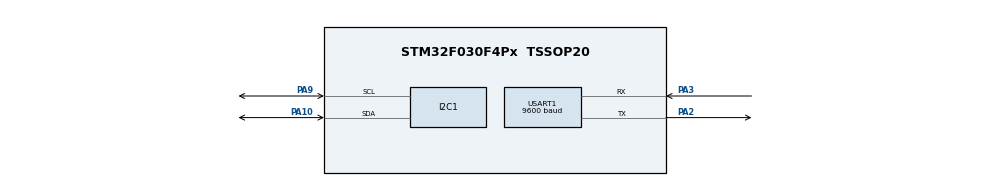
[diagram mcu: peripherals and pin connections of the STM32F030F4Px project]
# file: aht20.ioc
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I2C1.Timing=0x00201D2B
Mcu.Family=STM32F0
Mcu.Name=STM32F030F4Px
Mcu.Package=TSSOP20
PA10.Mode=I2C
PA10.Signal=I2C1_SDA
PA13.Mode=Serial_Wire
PA13.Signal=SYS_SWDIO
PA14.Mode=Serial_Wire
PA14.Signal=SYS_SWCLK
PA2.Mode=Asynchronous
PA2.Signal=USART1_TX
PA3.Mode=Asynchronous
PA3.Signal=USART1_RX
PA9.Mode=I2C
PA9.Signal=I2C1_SCL
ProjectManager.HeapSize=0x200
ProjectManager.StackSize=0x400
ProjectManager.TargetToolchain=EWARM V8.32
USART1.BaudRate=9600
USART1.VirtualMode-Asynchronous=VM_ASYNC
board=custom

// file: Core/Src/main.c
/* USER CODE BEGIN Header */
/**
  ******************************************************************************
  * @file           : main.c
  * @brief          : Main program body
  ******************************************************************************
  * @attention
  *
  * Copyright (c) 2025 STMicroelectronics.
  * All rights reserved.
  *
  * This software is licensed under terms that can be found in the LICENSE file
  * in the root directory of this software component.
  * If no LICENSE file comes with this software, it is provided AS-IS.
  *
  ******************************************************************************
  */
/* USER CODE END Header */
#include "main.h"

/* USER CODE BEGIN Includes */
#include "AHT20.h"
#include "stdio.h"

/* USER CODE END Includes */

I2C_HandleTypeDef hi2c1;

UART_HandleTypeDef huart1;

/* USER CODE BEGIN PV */
float temp = 0,humiditi = 0;
char ch[40];
/* USER CODE END PV */

void SystemClock_Config(void);
static void MX_GPIO_Init(void);
static void MX_I2C1_Init(void);
static void MX_USART1_UART_Init(void);

int main(void)
{

  /* MCU Configuration--------------------------------------------------------*/

  /* Reset of all peripherals, Initializes the Flash interface and the Systick. */
  HAL_Init();

  /* Configure the system clock */
  SystemClock_Config();

  /* Initialize all configured peripherals */
  MX_GPIO_Init();
  MX_I2C1_Init();
  MX_USART1_UART_Init();
  /* USER CODE BEGIN 2 */
 AHT20_init();
  HAL_StatusTypeDef res = AHT20_read(&temp,&humiditi);

  sprintf(ch,"%f",temp);
  HAL_UART_Transmit(&huart1,"temp = ",7,100);
    HAL_UART_Transmit(&huart1,ch,strlen(ch),100);
      HAL_UART_Transmit(&huart1," \r\n",3,100);

        sprintf(ch,"%f",humiditi);
  HAL_UART_Transmit(&huart1,"hum = ",6,100);
    HAL_UART_Transmit(&huart1,ch,strlen(ch),100);
      HAL_UART_Transmit(&huart1," \r\n",3,100);
  /* USER CODE END 2 */

  /* Infinite loop */
  while (1)
  {

  }
}

void SystemClock_Config(void)
{
  RCC_OscInitTypeDef RCC_OscInitStruct = {0};
  RCC_ClkInitTypeDef RCC_ClkInitStruct = {0};
  RCC_PeriphCLKInitTypeDef PeriphClkInit = {0};

  /** Initializes the RCC Oscillators according to the specified parameters
  * in the RCC_OscInitTypeDef structure.
  */
  RCC_OscInitStruct.OscillatorType = RCC_OSCILLATORTYPE_HSI;
  RCC_OscInitStruct.HSIState = RCC_HSI_ON;
  RCC_OscInitStruct.HSICalibrationValue = RCC_HSICALIBRATION_DEFAULT;
  RCC_OscInitStruct.PLL.PLLState = RCC_PLL_NONE;
  if (HAL_RCC_OscConfig(&RCC_OscInitStruct) != HAL_OK)
  {
    Error_Handler();
  }

  /** Initializes the CPU, AHB and APB buses clocks
  */
  RCC_ClkInitStruct.ClockType = RCC_CLOCKTYPE_HCLK|RCC_CLOCKTYPE_SYSCLK
                              |RCC_CLOCKTYPE_PCLK1;
  RCC_ClkInitStruct.SYSCLKSource = RCC_SYSCLKSOURCE_HSI;
  RCC_ClkInitStruct.AHBCLKDivider = RCC_SYSCLK_DIV1;
  RCC_ClkInitStruct.APB1CLKDivider = RCC_HCLK_DIV1;

  if (HAL_RCC_ClockConfig(&RCC_ClkInitStruct, FLASH_LATENCY_0) != HAL_OK)
  {
    Error_Handler();
  }
  PeriphClkInit.PeriphClockSelection = RCC_PERIPHCLK_USART1|RCC_PERIPHCLK_I2C1;
  PeriphClkInit.Usart1ClockSelection = RCC_USART1CLKSOURCE_PCLK1;
  PeriphClkInit.I2c1ClockSelection = RCC_I2C1CLKSOURCE_HSI;
  if (HAL_RCCEx_PeriphCLKConfig(&PeriphClkInit) != HAL_OK)
  {
    Error_Handler();
  }
}

static void MX_I2C1_Init(void)
{

  hi2c1.Instance = I2C1;
  hi2c1.Init.Timing = 0x00201D2B;
  hi2c1.Init.OwnAddress1 = 0;
  hi2c1.Init.AddressingMode = I2C_ADDRESSINGMODE_7BIT;
  hi2c1.Init.DualAddressMode = I2C_DUALADDRESS_DISABLE;
  hi2c1.Init.OwnAddress2 = 0;
  hi2c1.Init.OwnAddress2Masks = I2C_OA2_NOMASK;
  hi2c1.Init.GeneralCallMode = I2C_GENERALCALL_DISABLE;
  hi2c1.Init.NoStretchMode = I2C_NOSTRETCH_DISABLE;
  if (HAL_I2C_Init(&hi2c1) != HAL_OK)
  {
    Error_Handler();
  }

  /** Configure Analogue filter
  */
  if (HAL_I2CEx_ConfigAnalogFilter(&hi2c1, I2C_ANALOGFILTER_ENABLE) != HAL_OK)
  {
    Error_Handler();
  }

  /** Configure Digital filter
  */
  if (HAL_I2CEx_ConfigDigitalFilter(&hi2c1, 0) != HAL_OK)
  {
    Error_Handler();
  }

}

static void MX_USART1_UART_Init(void)
{

  huart1.Instance = USART1;
  huart1.Init.BaudRate = 9600;
  huart1.Init.WordLength = UART_WORDLENGTH_8B;
  huart1.Init.StopBits = UART_STOPBITS_1;
  huart1.Init.Parity = UART_PARITY_NONE;
  huart1.Init.Mode = UART_MODE_TX_RX;
  huart1.Init.HwFlowCtl = UART_HWCONTROL_NONE;
  huart1.Init.OverSampling = UART_OVERSAMPLING_16;
  huart1.Init.OneBitSampling = UART_ONE_BIT_SAMPLE_DISABLE;
  huart1.AdvancedInit.AdvFeatureInit = UART_ADVFEATURE_NO_INIT;
  if (HAL_UART_Init(&huart1) != HAL_OK)
  {
    Error_Handler();
  }

}

static void MX_GPIO_Init(void)
{

  /* GPIO Ports Clock Enable */
  __HAL_RCC_GPIOA_CLK_ENABLE();

}

void Error_Handler(void)
{
  __disable_irq();
  while (1)
  {
  }
}
